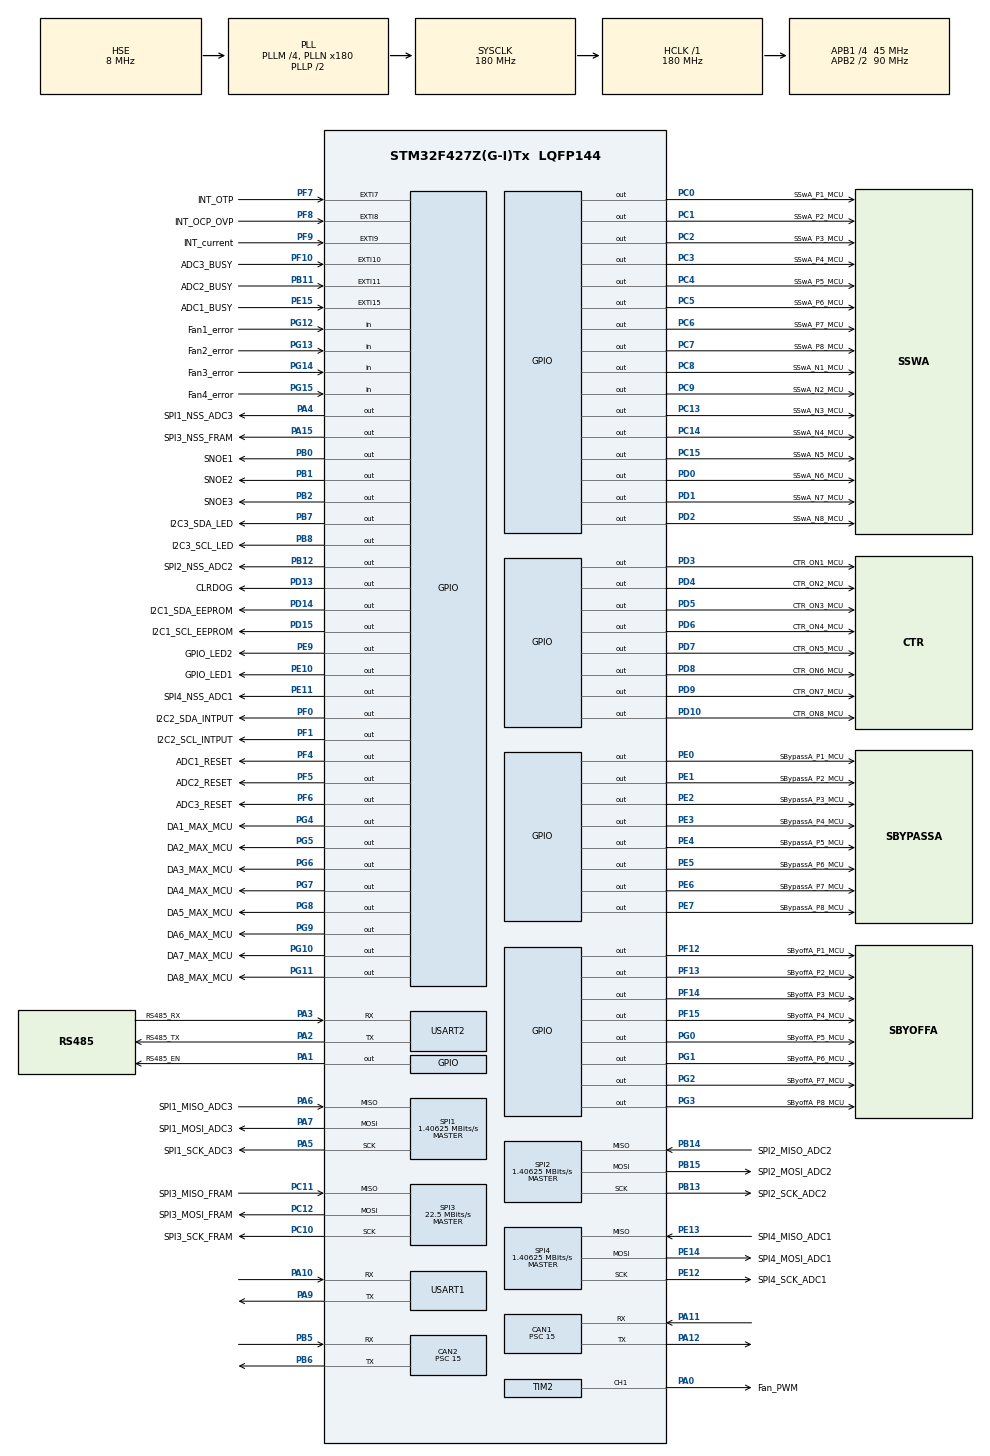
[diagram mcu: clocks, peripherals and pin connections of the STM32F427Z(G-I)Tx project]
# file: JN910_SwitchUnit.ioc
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CAN1.BS1=CAN_BS1_4TQ
CAN1.CalculateBaudRate=500000
CAN1.CalculateTimeBit=2000
CAN1.CalculateTimeQuantum=333.3333333333333
CAN1.Prescaler=15
CAN2.BS1=CAN_BS1_4TQ
CAN2.CalculateBaudRate=500000
CAN2.CalculateTimeBit=2000
CAN2.CalculateTimeQuantum=333.3333333333333
CAN2.Prescaler=15
Mcu.Family=STM32F4
Mcu.Name=STM32F427Z(G-I)Tx
Mcu.Package=LQFP144
NVIC.CAN1_RX0_IRQn=true\:1\:0\:true\:false\:true\:true\:true\:true
NVIC.CAN1_RX1_IRQn=true\:1\:0\:true\:false\:true\:true\:true\:true
NVIC.CAN2_RX0_IRQn=true\:1\:0\:true\:false\:true\:true\:true\:true
NVIC.CAN2_RX1_IRQn=true\:1\:0\:true\:false\:true\:true\:true\:true
NVIC.EXTI15_10_IRQn=true\:1\:0\:true\:false\:true\:true\:true\:true
NVIC.EXTI9_5_IRQn=true\:1\:0\:true\:false\:true\:true\:true\:true
NVIC.PriorityGroup=NVIC_PRIORITYGROUP_2
NVIC.TIM8_TRG_COM_TIM14_IRQn=true\:0\:0\:true\:false\:true\:false\:true\:true
NVIC.TimeBase=TIM8_TRG_COM_TIM14_IRQn
NVIC.TimeBaseIP=TIM14
NVIC.USART1_IRQn=true\:1\:0\:true\:false\:true\:true\:true\:true
NVIC.USART2_IRQn=true\:1\:0\:true\:false\:true\:true\:true\:true
PA0/WKUP.GPIO_Label=Fan_PWM
PA0/WKUP.Signal=S_TIM2_CH1_ETR
PA1.GPIO_Label=RS485_EN
PA1.Signal=GPIO_Output
PA10.Mode=Asynchronous
PA10.Signal=USART1_RX
PA11.Mode=CAN_Activate
PA11.Signal=CAN1_RX
PA12.Mode=CAN_Activate
PA12.Signal=CAN1_TX
PA13.Mode=Serial_Wire
PA13.Signal=SYS_JTMS-SWDIO
PA14.Mode=Serial_Wire
PA14.Signal=SYS_JTCK-SWCLK
PA15.GPIO_Label=SPI3_NSS_FRAM
PA15.GPIO_Speed=GPIO_SPEED_FREQ_HIGH
PA15.PinState=GPIO_PIN_SET
PA15.Signal=GPIO_Output
PA2.GPIO_Label=RS485_TX
PA2.Mode=Asynchronous
PA2.Signal=USART2_TX
PA3.GPIO_Label=RS485_RX
PA3.Mode=Asynchronous
PA3.Signal=USART2_RX
PA4.GPIO_Label=SPI1_NSS_ADC3
PA4.GPIO_Speed=GPIO_SPEED_FREQ_HIGH
PA4.PinState=GPIO_PIN_SET
PA4.Signal=GPIO_Output
PA5.GPIO_Label=SPI1_SCK_ADC3
PA5.Mode=Full_Duplex_Master
PA5.Signal=SPI1_SCK
PA6.GPIO_Label=SPI1_MISO_ADC3
PA6.Mode=Full_Duplex_Master
PA6.Signal=SPI1_MISO
PA7.GPIO_Label=SPI1_MOSI_ADC3
PA7.Mode=Full_Duplex_Master
PA7.Signal=SPI1_MOSI
PA9.Mode=Asynchronous
PA9.Signal=USART1_TX
PB0.GPIO_Label=SNOE1
PB0.PinState=GPIO_PIN_SET
PB0.Signal=GPIO_Output
PB1.GPIO_Label=SNOE2
PB1.PinState=GPIO_PIN_SET
PB1.Signal=GPIO_Output
PB11.GPIO_Label=ADC2_BUSY
PB11.Signal=GPXTI11
PB12.GPIO_Label=SPI2_NSS_ADC2
PB12.GPIO_Speed=GPIO_SPEED_FREQ_HIGH
PB12.PinState=GPIO_PIN_SET
PB12.Signal=GPIO_Output
PB13.GPIO_Label=SPI2_SCK_ADC2
PB13.Mode=Full_Duplex_Master
PB13.Signal=SPI2_SCK
PB14.GPIO_Label=SPI2_MISO_ADC2
PB14.Mode=Full_Duplex_Master
PB14.Signal=SPI2_MISO
PB15.GPIO_Label=SPI2_MOSI_ADC2
PB15.Mode=Full_Duplex_Master
PB15.Signal=SPI2_MOSI
PB2/BOOT1.GPIO_Label=SNOE3
PB2/BOOT1.PinState=GPIO_PIN_SET
PB2/BOOT1.Signal=GPIO_Output
PB5.Mode=CAN_Activate
PB5.Signal=CAN2_RX
PB6.Mode=CAN_Activate
PB6.Signal=CAN2_TX
PB7.GPIO_Label=I2C3_SDA_LED
PB7.GPIO_ModeDefaultOutputPP=GPIO_MODE_OUTPUT_OD
PB7.GPIO_PuPd=GPIO_PULLUP
PB7.GPIO_Speed=GPIO_SPEED_FREQ_HIGH
PB7.PinState=GPIO_PIN_SET
PB7.Signal=GPIO_Output
PB8.GPIO_Label=I2C3_SCL_LED
PB8.GPIO_ModeDefaultOutputPP=GPIO_MODE_OUTPUT_OD
PB8.GPIO_PuPd=GPIO_PULLUP
PB8.GPIO_Speed=GPIO_SPEED_FREQ_HIGH
PB8.PinState=GPIO_PIN_SET
PB8.Signal=GPIO_Output
PC0.GPIO_Label=SSwA_P1_MCU
PC0.Signal=GPIO_Output
PC1.GPIO_Label=SSwA_P2_MCU
PC1.Signal=GPIO_Output
PC10.GPIO_Label=SPI3_SCK_FRAM
PC10.Mode=Full_Duplex_Master
PC10.Signal=SPI3_SCK
PC11.GPIO_Label=SPI3_MISO_FRAM
PC11.Mode=Full_Duplex_Master
PC11.Signal=SPI3_MISO
PC12.GPIO_Label=SPI3_MOSI_FRAM
PC12.Mode=Full_Duplex_Master
PC12.Signal=SPI3_MOSI
PC13.GPIO_Label=SSwA_N3_MCU
PC13.Signal=GPIO_Output
PC14/OSC32_IN.GPIO_Label=SSwA_N4_MCU
PC14/OSC32_IN.Signal=GPIO_Output
PC15/OSC32_OUT.GPIO_Label=SSwA_N5_MCU
PC15/OSC32_OUT.Signal=GPIO_Output
PC2.GPIO_Label=SSwA_P3_MCU
PC2.Signal=GPIO_Output
PC3.GPIO_Label=SSwA_P4_MCU
PC3.Signal=GPIO_Output
PC4.GPIO_Label=SSwA_P5_MCU
PC4.Signal=GPIO_Output
PC5.GPIO_Label=SSwA_P6_MCU
PC5.Signal=GPIO_Output
PC6.GPIO_Label=SSwA_P7_MCU
PC6.Signal=GPIO_Output
PC7.GPIO_Label=SSwA_P8_MCU
PC7.Signal=GPIO_Output
PC8.GPIO_Label=SSwA_N1_MCU
PC8.Signal=GPIO_Output
PC9.GPIO_Label=SSwA_N2_MCU
PC9.Signal=GPIO_Output
PD0.GPIO_Label=SSwA_N6_MCU
PD0.Signal=GPIO_Output
PD1.GPIO_Label=SSwA_N7_MCU
PD1.Signal=GPIO_Output
PD10.GPIO_Label=CTR_ON8_MCU
PD10.Signal=GPIO_Output
PD13.GPIO_Label=CLRDOG
PD13.Signal=GPIO_Output
PD14.GPIO_Label=I2C1_SDA_EEPROM
PD14.GPIO_ModeDefaultOutputPP=GPIO_MODE_OUTPUT_OD
PD14.GPIO_PuPd=GPIO_PULLUP
PD14.GPIO_Speed=GPIO_SPEED_FREQ_HIGH
PD14.PinState=GPIO_PIN_SET
PD14.Signal=GPIO_Output
PD15.GPIO_Label=I2C1_SCL_EEPROM
PD15.GPIO_ModeDefaultOutputPP=GPIO_MODE_OUTPUT_OD
PD15.GPIO_PuPd=GPIO_PULLUP
PD15.GPIO_Speed=GPIO_SPEED_FREQ_HIGH
PD15.PinState=GPIO_PIN_SET
PD15.Signal=GPIO_Output
PD2.GPIO_Label=SSwA_N8_MCU
PD2.Signal=GPIO_Output
PD3.GPIO_Label=CTR_ON1_MCU
PD3.Signal=GPIO_Output
PD4.GPIO_Label=CTR_ON2_MCU
PD4.Signal=GPIO_Output
PD5.GPIO_Label=CTR_ON3_MCU
PD5.Signal=GPIO_Output
PD6.GPIO_Label=CTR_ON4_MCU
PD6.Signal=GPIO_Output
PD7.GPIO_Label=CTR_ON5_MCU
PD7.Signal=GPIO_Output
PD8.GPIO_Label=CTR_ON6_MCU
PD8.Signal=GPIO_Output
PD9.GPIO_Label=CTR_ON7_MCU
PD9.Signal=GPIO_Output
PE0.GPIO_Label=SBypassA_P1_MCU
PE0.Signal=GPIO_Output
PE1.GPIO_Label=SBypassA_P2_MCU
PE1.Signal=GPIO_Output
PE10.GPIO_Label=GPIO_LED1
PE10.PinState=GPIO_PIN_SET
PE10.Signal=GPIO_Output
PE11.GPIO_Label=SPI4_NSS_ADC1
PE11.GPIO_Speed=GPIO_SPEED_FREQ_HIGH
PE11.PinState=GPIO_PIN_SET
PE11.Signal=GPIO_Output
PE12.GPIO_Label=SPI4_SCK_ADC1
PE12.Mode=Full_Duplex_Master
PE12.Signal=SPI4_SCK
PE13.GPIO_Label=SPI4_MISO_ADC1
PE13.Mode=Full_Duplex_Master
PE13.Signal=SPI4_MISO
PE14.GPIO_Label=SPI4_MOSI_ADC1
PE14.Mode=Full_Duplex_Master
PE14.Signal=SPI4_MOSI
PE15.GPIO_Label=ADC1_BUSY
PE15.Signal=GPXTI15
PE2.GPIO_Label=SBypassA_P3_MCU
PE2.Signal=GPIO_Output
PE3.GPIO_Label=SBypassA_P4_MCU
PE3.Signal=GPIO_Output
PE4.GPIO_Label=SBypassA_P5_MCU
PE4.Signal=GPIO_Output
PE5.GPIO_Label=SBypassA_P6_MCU
PE5.Signal=GPIO_Output
PE6.GPIO_Label=SBypassA_P7_MCU
PE6.Signal=GPIO_Output
PE7.GPIO_Label=SBypassA_P8_MCU
PE7.Signal=GPIO_Output
PE9.GPIO_Label=GPIO_LED2
PE9.PinState=GPIO_PIN_SET
PE9.Signal=GPIO_Output
PF0.GPIO_Label=I2C2_SDA_INTPUT
PF0.GPIO_ModeDefaultOutputPP=GPIO_MODE_OUTPUT_OD
PF0.GPIO_PuPd=GPIO_PULLUP
PF0.GPIO_Speed=GPIO_SPEED_FREQ_HIGH
PF0.PinState=GPIO_PIN_SET
PF0.Signal=GPIO_Output
PF1.GPIO_Label=I2C2_SCL_INTPUT
PF1.GPIO_ModeDefaultOutputPP=GPIO_MODE_OUTPUT_OD
PF1.GPIO_PuPd=GPIO_PULLUP
PF1.GPIO_Speed=GPIO_SPEED_FREQ_HIGH
PF1.PinState=GPIO_PIN_SET
PF1.Signal=GPIO_Output
PF10.GPIO_Label=ADC3_BUSY
PF10.Signal=GPXTI10
PF12.GPIO_Label=SByoffA_P1_MCU
PF12.Signal=GPIO_Output
PF13.GPIO_Label=SByoffA_P2_MCU
PF13.Signal=GPIO_Output
PF14.GPIO_Label=SByoffA_P3_MCU
PF14.Signal=GPIO_Output
PF15.GPIO_Label=SByoffA_P4_MCU
PF15.Signal=GPIO_Output
PF4.GPIO_Label=ADC1_RESET
PF4.PinState=GPIO_PIN_SET
PF4.Signal=GPIO_Output
PF5.GPIO_Label=ADC2_RESET
PF5.PinState=GPIO_PIN_SET
PF5.Signal=GPIO_Output
PF6.GPIO_Label=ADC3_RESET
PF6.PinState=GPIO_PIN_SET
PF6.Signal=GPIO_Output
PF7.GPIO_Label=INT_OTP
PF7.Signal=GPXTI7
PF8.GPIO_Label=INT_OCP_OVP
PF8.Signal=GPXTI8
PF9.GPIO_Label=INT_current
PF9.Signal=GPXTI9
PG0.GPIO_Label=SByoffA_P5_MCU
PG0.Signal=GPIO_Output
PG1.GPIO_Label=SByoffA_P6_MCU
PG1.Signal=GPIO_Output
PG10.GPIO_Label=DA7_MAX_MCU
PG10.Signal=GPIO_Output
PG11.GPIO_Label=DA8_MAX_MCU
PG11.Signal=GPIO_Output
PG12.GPIO_Label=Fan1_error
PG12.Signal=GPIO_Input
PG13.GPIO_Label=Fan2_error
PG13.Signal=GPIO_Input
PG14.GPIO_Label=Fan3_error
PG14.Signal=GPIO_Input
PG15.GPIO_Label=Fan4_error
PG15.Signal=GPIO_Input
PG2.GPIO_Label=SByoffA_P7_MCU
PG2.Signal=GPIO_Output
PG3.GPIO_Label=SByoffA_P8_MCU
PG3.Signal=GPIO_Output
PG4.GPIO_Label=DA1_MAX_MCU
PG4.Signal=GPIO_Output
PG5.GPIO_Label=DA2_MAX_MCU
PG5.Signal=GPIO_Output
PG6.GPIO_Label=DA3_MAX_MCU
PG6.Signal=GPIO_Output
PG7.GPIO_Label=DA4_MAX_MCU
PG7.Signal=GPIO_Output
PG8.GPIO_Label=DA5_MAX_MCU
PG8.Signal=GPIO_Output
PG9.GPIO_Label=DA6_MAX_MCU
PG9.Signal=GPIO_Output
PH0/OSC_IN.Mode=HSE-External-Oscillator
PH0/OSC_IN.Signal=RCC_OSC_IN
PH1/OSC_OUT.Mode=HSE-External-Oscillator
PH1/OSC_OUT.Signal=RCC_OSC_OUT
ProjectManager.HeapSize=0x200
ProjectManager.StackSize=0x400
ProjectManager.TargetToolchain=MDK-ARM V5.32
RCC.48MHZClocksFreq_Value=45000000
RCC.AHBFreq_Value=180000000
RCC.APB1CLKDivider=RCC_HCLK_DIV4
RCC.APB1Freq_Value=45000000
RCC.APB1TimFreq_Value=90000000
RCC.APB2CLKDivider=RCC_HCLK_DIV2
RCC.APB2Freq_Value=90000000
RCC.APB2TimFreq_Value=180000000
RCC.CortexFreq_Value=180000000
RCC.HCLKFreq_Value=180000000
RCC.HSE_VALUE=8000000
RCC.HSI_VALUE=16000000
RCC.LSE_VALUE=32768
RCC.PLLM=4
RCC.PLLN=180
RCC.PLLQ=8
RCC.PLLSourceVirtual=RCC_PLLSOURCE_HSE
RCC.SYSCLKFreq_VALUE=180000000
RCC.SYSCLKSource=RCC_SYSCLKSOURCE_PLLCLK
RCC.VCOOutputFreq_Value=360000000
SH.S_TIM2_CH1_ETR.0=TIM2_CH1,PWM Generation1 CH1
SPI1.BaudRatePrescaler=SPI_BAUDRATEPRESCALER_64
SPI1.CLKPhase=SPI_PHASE_2EDGE
SPI1.CalculateBaudRate=1.40625 MBits/s
SPI1.Direction=SPI_DIRECTION_2LINES
SPI1.Mode=SPI_MODE_MASTER
SPI1.VirtualType=VM_MASTER
SPI2.BaudRatePrescaler=SPI_BAUDRATEPRESCALER_32
SPI2.CLKPhase=SPI_PHASE_2EDGE
SPI2.CalculateBaudRate=1.40625 MBits/s
SPI2.Direction=SPI_DIRECTION_2LINES
SPI2.Mode=SPI_MODE_MASTER
SPI2.VirtualType=VM_MASTER
SPI3.BaudRatePrescaler=SPI_BAUDRATEPRESCALER_2
SPI3.CalculateBaudRate=22.5 MBits/s
SPI3.Direction=SPI_DIRECTION_2LINES
SPI3.Mode=SPI_MODE_MASTER
SPI3.VirtualType=VM_MASTER
SPI4.BaudRatePrescaler=SPI_BAUDRATEPRESCALER_64
SPI4.CLKPhase=SPI_PHASE_2EDGE
SPI4.CalculateBaudRate=1.40625 MBits/s
SPI4.Direction=SPI_DIRECTION_2LINES
SPI4.Mode=SPI_MODE_MASTER
SPI4.VirtualType=VM_MASTER
TIM2.AutoReloadPreload=TIM_AUTORELOAD_PRELOAD_ENABLE
TIM2.Channel-PWM\ Generation1\ CH1=TIM_CHANNEL_1
TIM2.Period=1000-1
TIM2.Prescaler=9-1
TIM2.Pulse-PWM\ Generation1\ CH1=20
USART1.VirtualMode=VM_ASYNC
USART2.VirtualMode=VM_ASYNC
VP_RNG_VS_RNG.Mode=RNG_Activate
VP_SYS_VS_tim14.Mode=TIM14
board=custom

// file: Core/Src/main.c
/* USER CODE BEGIN Header */
/**
 ******************************************************************************
 * @file           : main.c
 * @brief          : Main program body
 ******************************************************************************
 * @attention
 *
 * Copyright (c) 2022 STMicroelectronics.
 * All rights reserved.
 *
 * This software is licensed under terms that can be found in the LICENSE file
 * in the root directory of this software component.
 * If no LICENSE file comes with this software, it is provided AS-IS.
 *
 ******************************************************************************
 */
/* USER CODE END Header */
#include "main.h"
#include "can.h"
#include "rng.h"
#include "spi.h"
#include "tim.h"
#include "usart.h"
#include "gpio.h"
#include "Bsp_NCA9555.h"

/* USER CODE BEGIN PV */

/*-------------------------------RTX操作系统对象------------------------------*/
/* 任务句柄 */
osThreadId_t ThreadIdStart = NULL; //起始任务

/* 任务属性设置 */
const osThreadAttr_t ThreadStart_Attr = //起始任务参数配置
	{
		.name = "osRtxStartThread",
		.attr_bits = osThreadDetached,
		.priority = osPriorityNormal,
		.stack_size = 2048,
};

/* 信号量属性 */

/* 定时器属性 */

/* USER CODE END PV */

void SystemClock_Config(void);

/* USER CODE BEGIN 0 */

int main(void)
{

	/* MCU Configuration--------------------------------------------------------*/

	/* Reset of all peripherals, Initializes the Flash interface and the Systick. */
	HAL_Init();

	/* Configure the system clock */
	SystemClock_Config();

	/* Initialize all configured peripherals */
	MX_GPIO_Init();
	MX_RNG_Init();
	MX_SPI1_Init();
	MX_SPI2_Init();
	MX_SPI3_Init();
	MX_SPI4_Init();
	MX_USART1_UART_Init();
	MX_USART2_UART_Init();
	MX_TIM2_Init();

	/* USER CODE BEGIN 2 */
	BspInit();
	MX_CAN1_Init();
	MX_CAN2_Init();
	/* 内核初始化 */
	osKernelInitialize();

	/* 创建启动任务 */
	ThreadIdStart = osThreadNew(AppTaskStart, NULL, &ThreadStart_Attr);

	/* 开启多任务 */
	osKernelStart();

	/* USER CODE END 2 */
	/* USER CODE BEGIN WHILE */
	while (1)
	{
	}
	/* USER CODE END 3 */
}

void SystemClock_Config(void)
{
	RCC_OscInitTypeDef RCC_OscInitStruct = {0};
	RCC_ClkInitTypeDef RCC_ClkInitStruct = {0};

	/** Configure the main internal regulator output voltage
	 */
	__HAL_RCC_PWR_CLK_ENABLE();
	__HAL_PWR_VOLTAGESCALING_CONFIG(PWR_REGULATOR_VOLTAGE_SCALE1);

	/** Initializes the RCC Oscillators according to the specified parameters
	 * in the RCC_OscInitTypeDef structure.
	 */
	RCC_OscInitStruct.OscillatorType = RCC_OSCILLATORTYPE_HSE;
	RCC_OscInitStruct.HSEState = RCC_HSE_ON;
	RCC_OscInitStruct.PLL.PLLState = RCC_PLL_ON;
	RCC_OscInitStruct.PLL.PLLSource = RCC_PLLSOURCE_HSE;
	RCC_OscInitStruct.PLL.PLLM = 4;
	RCC_OscInitStruct.PLL.PLLN = 180;
	RCC_OscInitStruct.PLL.PLLP = RCC_PLLP_DIV2;
	RCC_OscInitStruct.PLL.PLLQ = 8;
	if (HAL_RCC_OscConfig(&RCC_OscInitStruct) != HAL_OK)
	{
		Error_Handler();
	}

	/** Activate the Over-Drive mode
	 */
	if (HAL_PWREx_EnableOverDrive() != HAL_OK)
	{
		Error_Handler();
	}

	/** Initializes the CPU, AHB and APB buses clocks
	 */
	RCC_ClkInitStruct.ClockType = RCC_CLOCKTYPE_HCLK | RCC_CLOCKTYPE_SYSCLK | RCC_CLOCKTYPE_PCLK1 | RCC_CLOCKTYPE_PCLK2;
	RCC_ClkInitStruct.SYSCLKSource = RCC_SYSCLKSOURCE_PLLCLK;
	RCC_ClkInitStruct.AHBCLKDivider = RCC_SYSCLK_DIV1;
	RCC_ClkInitStruct.APB1CLKDivider = RCC_HCLK_DIV4;
	RCC_ClkInitStruct.APB2CLKDivider = RCC_HCLK_DIV2;

	if (HAL_RCC_ClockConfig(&RCC_ClkInitStruct, FLASH_LATENCY_5) != HAL_OK)
	{
		Error_Handler();
	}
}

void HAL_TIM_PeriodElapsedCallback(TIM_HandleTypeDef *htim)
{
	if (htim->Instance == TIM14)
	{
		HAL_IncTick();
	}
}

void Error_Handler(void)
{
	__disable_irq();
	while (1)
	{
	}
}
